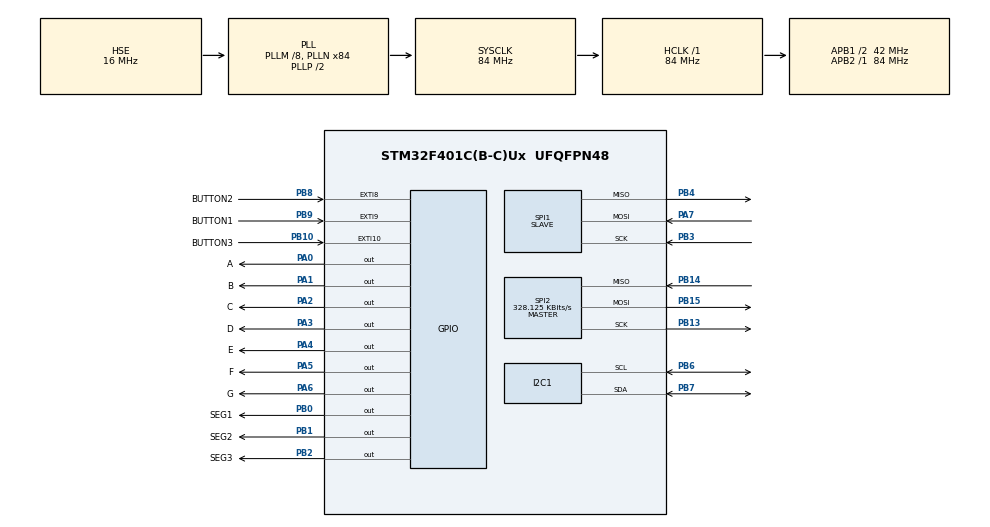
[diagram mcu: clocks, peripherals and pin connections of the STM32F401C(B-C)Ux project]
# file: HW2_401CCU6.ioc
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Mcu.Family=STM32F4
Mcu.Name=STM32F401C(B-C)Ux
Mcu.Package=UFQFPN48
NVIC.EXTI15_10_IRQn=true\:4\:0\:true\:false\:true\:true\:true\:true
NVIC.EXTI9_5_IRQn=true\:3\:0\:true\:false\:true\:true\:true\:true
NVIC.PriorityGroup=NVIC_PRIORITYGROUP_4
NVIC.SPI1_IRQn=true\:3\:0\:true\:false\:true\:true\:true\:true
NVIC.SPI2_IRQn=true\:3\:0\:true\:false\:true\:true\:true\:true
PA0-WKUP.GPIO_Label=A
PA0-WKUP.Signal=GPIO_Output
PA1.GPIO_Label=B
PA1.Signal=GPIO_Output
PA13.Mode=Serial_Wire
PA13.Signal=SYS_JTMS-SWDIO
PA14.Mode=Serial_Wire
PA14.Signal=SYS_JTCK-SWCLK
PA2.GPIO_Label=C
PA2.Signal=GPIO_Output
PA3.GPIO_Label=D
PA3.Signal=GPIO_Output
PA4.GPIO_Label=E
PA4.Signal=GPIO_Output
PA5.GPIO_Label=F
PA5.Signal=GPIO_Output
PA6.GPIO_Label=G
PA6.Signal=GPIO_Output
PA7.GPIO_Speed=GPIO_SPEED_FREQ_MEDIUM
PA7.Mode=Full_Duplex_Slave
PA7.Signal=SPI1_MOSI
PB0.GPIO_Label=SEG1
PB0.Signal=GPIO_Output
PB1.GPIO_Label=SEG2
PB1.Signal=GPIO_Output
PB10.GPIO_Label=BUTTON3
PB10.GPIO_ModeDefaultEXTI=GPIO_MODE_IT_RISING
PB10.Signal=GPXTI10
PB13.GPIO_Speed=GPIO_SPEED_FREQ_MEDIUM
PB13.Mode=Full_Duplex_Master
PB13.Signal=SPI2_SCK
PB14.GPIO_Speed=GPIO_SPEED_FREQ_MEDIUM
PB14.Mode=Full_Duplex_Master
PB14.Signal=SPI2_MISO
PB15.GPIO_Speed=GPIO_SPEED_FREQ_MEDIUM
PB15.Mode=Full_Duplex_Master
PB15.Signal=SPI2_MOSI
PB2.GPIO_Label=SEG3
PB2.Signal=GPIO_Output
PB3.GPIO_Speed=GPIO_SPEED_FREQ_MEDIUM
PB3.Mode=Full_Duplex_Slave
PB3.Signal=SPI1_SCK
PB4.GPIO_Speed=GPIO_SPEED_FREQ_MEDIUM
PB4.Mode=Full_Duplex_Slave
PB4.Signal=SPI1_MISO
PB6.GPIO_Speed=GPIO_SPEED_FREQ_MEDIUM
PB6.Mode=I2C
PB6.Signal=I2C1_SCL
PB7.GPIO_Speed=GPIO_SPEED_FREQ_MEDIUM
PB7.Mode=I2C
PB7.Signal=I2C1_SDA
PB8.GPIO_Label=BUTTON2
PB8.Signal=GPXTI8
PB9.GPIO_Label=BUTTON1
PB9.Signal=GPXTI9
PH0\ -\ OSC_IN.Mode=HSE-External-Oscillator
PH0\ -\ OSC_IN.Signal=RCC_OSC_IN
PH1\ -\ OSC_OUT.Mode=HSE-External-Oscillator
PH1\ -\ OSC_OUT.Signal=RCC_OSC_OUT
ProjectManager.HeapSize=0x200
ProjectManager.StackSize=0x400
ProjectManager.TargetToolchain=STM32CubeIDE
RCC.48MHZClocksFreq_Value=42000000
RCC.AHBFreq_Value=84000000
RCC.APB1CLKDivider=RCC_HCLK_DIV2
RCC.APB1Freq_Value=42000000
RCC.APB1TimFreq_Value=84000000
RCC.APB2Freq_Value=84000000
RCC.APB2TimFreq_Value=84000000
RCC.CortexFreq_Value=84000000
RCC.EnbaleCSS=true
RCC.HCLKFreq_Value=84000000
RCC.HSE_VALUE=16000000
RCC.HSI_VALUE=16000000
RCC.LSE_VALUE=32768
RCC.PLLM=8
RCC.PLLN=84
RCC.PLLSourceVirtual=RCC_PLLSOURCE_HSE
RCC.SYSCLKFreq_VALUE=84000000
RCC.SYSCLKSource=RCC_SYSCLKSOURCE_PLLCLK
RCC.VCOOutputFreq_Value=168000000
SPI1.Direction=SPI_DIRECTION_2LINES
SPI1.Mode=SPI_MODE_SLAVE
SPI1.VirtualType=VM_SLAVE
SPI2.BaudRatePrescaler=SPI_BAUDRATEPRESCALER_128
SPI2.CalculateBaudRate=328.125 KBits/s
SPI2.Direction=SPI_DIRECTION_2LINES
SPI2.Mode=SPI_MODE_MASTER
SPI2.VirtualType=VM_MASTER
board=custom

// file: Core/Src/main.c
/* USER CODE BEGIN Header */
/**
  ******************************************************************************
  * @file           : main.c
  * @brief          : Main program body
  ******************************************************************************
  * @attention
  *
  * Copyright (c) 2025 STMicroelectronics.
  * All rights reserved.
  *
  * This software is licensed under terms that can be found in the LICENSE file
  * in the root directory of this software component.
  * If no LICENSE file comes with this software, it is provided AS-IS.
  *
  ******************************************************************************
  */
/* USER CODE END Header */
#include "main.h"

/* USER CODE BEGIN Includes */

#include "My_code_401CCU.h"

/* USER CODE END Includes */

I2C_HandleTypeDef hi2c1;

SPI_HandleTypeDef hspi1;
SPI_HandleTypeDef hspi2;

/* USER CODE BEGIN PV */

uint8_t xRx = 0;
uint8_t xTx = 111;
extern volatile uint8_t Flag_Go_Rx;
extern volatile uint16_t Counter;

/* USER CODE END PV */

void SystemClock_Config(void);
static void MX_GPIO_Init(void);
static void MX_I2C1_Init(void);
static void MX_SPI1_Init(void);
static void MX_SPI2_Init(void);

int main(void)
{

  /* MCU Configuration--------------------------------------------------------*/

  /* Reset of all peripherals, Initializes the Flash interface and the Systick. */
  HAL_Init();

  /* Configure the system clock */
  SystemClock_Config();

  /* Initialize all configured peripherals */
  MX_GPIO_Init();
  MX_I2C1_Init();
  MX_SPI1_Init();
  MX_SPI2_Init();

  /* Infinite loop */
  /* USER CODE BEGIN WHILE */
  while (1)
  {
	  static uint32_t Timer = 0;

	  if ((HAL_GetTick() - Timer) > 1)
	  {
		  Timer = HAL_GetTick();

		  Update_LED ();
	  }

	  if (Flag_Go_Rx == 1)
	  {
		  Flag_Go_Rx = 0;

		  HAL_SPI_Receive_IT (& hspi1, & xRx, 1);

		  HAL_SPI_Transmit_IT (& hspi2, & xTx, 1);
	  }

    /* USER CODE END WHILE */

  }
}

void SystemClock_Config(void)
{
  RCC_OscInitTypeDef RCC_OscInitStruct = {0};
  RCC_ClkInitTypeDef RCC_ClkInitStruct = {0};

  /** Configure the main internal regulator output voltage
  */
  __HAL_RCC_PWR_CLK_ENABLE();
  __HAL_PWR_VOLTAGESCALING_CONFIG(PWR_REGULATOR_VOLTAGE_SCALE2);

  /** Initializes the RCC Oscillators according to the specified parameters
  * in the RCC_OscInitTypeDef structure.
  */
  RCC_OscInitStruct.OscillatorType = RCC_OSCILLATORTYPE_HSE;
  RCC_OscInitStruct.HSEState = RCC_HSE_ON;
  RCC_OscInitStruct.PLL.PLLState = RCC_PLL_ON;
  RCC_OscInitStruct.PLL.PLLSource = RCC_PLLSOURCE_HSE;
  RCC_OscInitStruct.PLL.PLLM = 8;
  RCC_OscInitStruct.PLL.PLLN = 84;
  RCC_OscInitStruct.PLL.PLLP = RCC_PLLP_DIV2;
  RCC_OscInitStruct.PLL.PLLQ = 4;
  if (HAL_RCC_OscConfig(&RCC_OscInitStruct) != HAL_OK)
  {
    Error_Handler();
  }

  /** Initializes the CPU, AHB and APB buses clocks
  */
  RCC_ClkInitStruct.ClockType = RCC_CLOCKTYPE_HCLK|RCC_CLOCKTYPE_SYSCLK
                              |RCC_CLOCKTYPE_PCLK1|RCC_CLOCKTYPE_PCLK2;
  RCC_ClkInitStruct.SYSCLKSource = RCC_SYSCLKSOURCE_PLLCLK;
  RCC_ClkInitStruct.AHBCLKDivider = RCC_SYSCLK_DIV1;
  RCC_ClkInitStruct.APB1CLKDivider = RCC_HCLK_DIV2;
  RCC_ClkInitStruct.APB2CLKDivider = RCC_HCLK_DIV1;

  if (HAL_RCC_ClockConfig(&RCC_ClkInitStruct, FLASH_LATENCY_2) != HAL_OK)
  {
    Error_Handler();
  }

  /** Enables the Clock Security System
  */
  HAL_RCC_EnableCSS();
}

static void MX_I2C1_Init(void)
{

  hi2c1.Instance = I2C1;
  hi2c1.Init.ClockSpeed = 100000;
  hi2c1.Init.DutyCycle = I2C_DUTYCYCLE_2;
  hi2c1.Init.OwnAddress1 = 0;
  hi2c1.Init.AddressingMode = I2C_ADDRESSINGMODE_7BIT;
  hi2c1.Init.DualAddressMode = I2C_DUALADDRESS_DISABLE;
  hi2c1.Init.OwnAddress2 = 0;
  hi2c1.Init.GeneralCallMode = I2C_GENERALCALL_DISABLE;
  hi2c1.Init.NoStretchMode = I2C_NOSTRETCH_DISABLE;
  if (HAL_I2C_Init(&hi2c1) != HAL_OK)
  {
    Error_Handler();
  }

}

static void MX_SPI1_Init(void)
{

  /* SPI1 parameter configuration*/
  hspi1.Instance = SPI1;
  hspi1.Init.Mode = SPI_MODE_SLAVE;
  hspi1.Init.Direction = SPI_DIRECTION_2LINES;
  hspi1.Init.DataSize = SPI_DATASIZE_8BIT;
  hspi1.Init.CLKPolarity = SPI_POLARITY_LOW;
  hspi1.Init.CLKPhase = SPI_PHASE_1EDGE;
  hspi1.Init.NSS = SPI_NSS_SOFT;
  hspi1.Init.FirstBit = SPI_FIRSTBIT_MSB;
  hspi1.Init.TIMode = SPI_TIMODE_DISABLE;
  hspi1.Init.CRCCalculation = SPI_CRCCALCULATION_DISABLE;
  hspi1.Init.CRCPolynomial = 10;
  if (HAL_SPI_Init(&hspi1) != HAL_OK)
  {
    Error_Handler();
  }

}

static void MX_SPI2_Init(void)
{

  /* SPI2 parameter configuration*/
  hspi2.Instance = SPI2;
  hspi2.Init.Mode = SPI_MODE_MASTER;
  hspi2.Init.Direction = SPI_DIRECTION_2LINES;
  hspi2.Init.DataSize = SPI_DATASIZE_8BIT;
  hspi2.Init.CLKPolarity = SPI_POLARITY_LOW;
  hspi2.Init.CLKPhase = SPI_PHASE_1EDGE;
  hspi2.Init.NSS = SPI_NSS_SOFT;
  hspi2.Init.BaudRatePrescaler = SPI_BAUDRATEPRESCALER_128;
  hspi2.Init.FirstBit = SPI_FIRSTBIT_MSB;
  hspi2.Init.TIMode = SPI_TIMODE_DISABLE;
  hspi2.Init.CRCCalculation = SPI_CRCCALCULATION_DISABLE;
  hspi2.Init.CRCPolynomial = 10;
  if (HAL_SPI_Init(&hspi2) != HAL_OK)
  {
    Error_Handler();
  }

}

static void MX_GPIO_Init(void)
{
  GPIO_InitTypeDef GPIO_InitStruct = {0};

  /* GPIO Ports Clock Enable */
  __HAL_RCC_GPIOH_CLK_ENABLE();
  __HAL_RCC_GPIOA_CLK_ENABLE();
  __HAL_RCC_GPIOB_CLK_ENABLE();

  /*Configure GPIO pin Output Level */
  HAL_GPIO_WritePin(GPIOA, A_Pin|B_Pin|C_Pin|D_Pin
                          |E_Pin|F_Pin|G_Pin, GPIO_PIN_RESET);

  /*Configure GPIO pin Output Level */
  HAL_GPIO_WritePin(GPIOB, SEG1_Pin|SEG2_Pin|SEG3_Pin, GPIO_PIN_RESET);

  /*Configure GPIO pins : A_Pin B_Pin C_Pin D_Pin
                           E_Pin F_Pin G_Pin */
  GPIO_InitStruct.Pin = A_Pin|B_Pin|C_Pin|D_Pin
                          |E_Pin|F_Pin|G_Pin;
  GPIO_InitStruct.Mode = GPIO_MODE_OUTPUT_PP;
  GPIO_InitStruct.Pull = GPIO_NOPULL;
  GPIO_InitStruct.Speed = GPIO_SPEED_FREQ_LOW;
  HAL_GPIO_Init(GPIOA, &GPIO_InitStruct);

  /*Configure GPIO pins : SEG1_Pin SEG2_Pin SEG3_Pin */
  GPIO_InitStruct.Pin = SEG1_Pin|SEG2_Pin|SEG3_Pin;
  GPIO_InitStruct.Mode = GPIO_MODE_OUTPUT_PP;
  GPIO_InitStruct.Pull = GPIO_NOPULL;
  GPIO_InitStruct.Speed = GPIO_SPEED_FREQ_LOW;
  HAL_GPIO_Init(GPIOB, &GPIO_InitStruct);

  /*Configure GPIO pins : BUTTON3_Pin BUTTON2_Pin BUTTON1_Pin */
  GPIO_InitStruct.Pin = BUTTON3_Pin|BUTTON2_Pin|BUTTON1_Pin;
  GPIO_InitStruct.Mode = GPIO_MODE_IT_RISING;
  GPIO_InitStruct.Pull = GPIO_NOPULL;
  HAL_GPIO_Init(GPIOB, &GPIO_InitStruct);

  /* EXTI interrupt init*/
  HAL_NVIC_SetPriority(EXTI9_5_IRQn, 3, 0);
  HAL_NVIC_EnableIRQ(EXTI9_5_IRQn);

  HAL_NVIC_SetPriority(EXTI15_10_IRQn, 4, 0);
  HAL_NVIC_EnableIRQ(EXTI15_10_IRQn);

}

void Error_Handler(void)
{
  __disable_irq();
  while (1)
  {
  }
}
